AUTOSAR XML (schema 4-3-0)
package /ComponentTypes
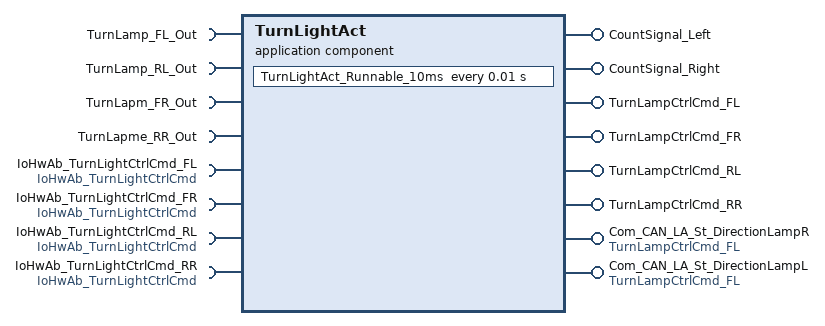
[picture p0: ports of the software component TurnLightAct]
  application sw component type TurnLightAct
    6 x provide port:
      CountSignal_Left: nonqueued-sender-com-spec{data-element=u8_Signal, init-value=0}, provided-interface=CountSignal_Left
      CountSignal_Right: nonqueued-sender-com-spec{data-element=u8_Signal, init-value=0}, provided-interface=CountSignal_Right
      TurnLampCtrlCmd_FL: nonqueued-sender-com-spec{data-element=u8_signal, init-value=0}, provided-interface=TurnLampCtrlCmd_FL
      TurnLampCtrlCmd_FR: nonqueued-sender-com-spec{data-element=u8_signa, init-value=0}, provided-interface=TurnLampCtrlCmd_FR
      TurnLampCtrlCmd_RL: nonqueued-sender-com-spec{data-element=u8_signal, init-value=0}, provided-interface=TurnLampCtrlCmd_RL
      TurnLampCtrlCmd_RR: nonqueued-sender-com-spec{data-element=u8_signal, init-value=0}, provided-interface=TurnLampCtrlCmd_RR
    4 x require port, all with nonqueued-receiver-com-spec{data-element=u8_Signal, init-value=0}:
      TurnLamp_FL_Out: required-interface=TurnLamp_FL_Out
      TurnLamp_RL_Out: required-interface=TurnLamp_RL_Out
      TurnLapm_FR_Out: required-interface=TurnLapm_FR_Out
      TurnLapme_RR_Out: required-interface=TurnLapme_RR_Out
    provide port Com_CAN_LA_St_DirectionLampR: nonqueued-sender-com-spec{data-element=u8_signal, init-value=0}, provided-interface=TurnLampCtrlCmd_FL
    provide port Com_CAN_LA_St_DirectionLampL: nonqueued-sender-com-spec{data-element=u8_signal, init-value=0}, provided-interface=TurnLampCtrlCmd_FL
    4 x require port, all with client-com-spec=Operation, required-interface=IoHwAb_TurnLightCtrlCmd:
      IoHwAb_TurnLightCtrlCmd_FL
      IoHwAb_TurnLightCtrlCmd_FR
      IoHwAb_TurnLightCtrlCmd_RL
      IoHwAb_TurnLightCtrlCmd_RR
    behavior TurnLightAct_InternalBehavior
      timing event TMT_Runnable_10ms: start-on-event=TurnLightAct_Runnable_10ms, period=0.01
      runnable TurnLightAct_Runnable_10ms: minimum-start-interval=0.01
        data-receive-point-by-arguments:
          4 x access:
            REC_TurnLamp_FL_Out_u8_Signal: accessed-variable=TurnLamp_FL_Out.u8_Signal
            REC_TurnLamp_RL_Out_u8_Signal: accessed-variable=TurnLamp_RL_Out.u8_Signal
            REC_TurnLapm_FR_Out_u8_Signal: accessed-variable=TurnLapm_FR_Out.u8_Signal
            REC_TurnLapme_RR_Out_u8_Signal: accessed-variable=TurnLapme_RR_Out.u8_Signal
        data-send-points:
          8 x access:
            SEND_CountSignal_Left_u8_Signal: accessed-variable=CountSignal_Left.u8_Signal
            SEND_CountSignal_Right_u8_Signal: accessed-variable=CountSignal_Right.u8_Signal
            SEND_TurnLampCtrlCmd_FL_u8_signal: accessed-variable=TurnLampCtrlCmd_FL.u8_signal
            SEND_TurnLampCtrlCmd_FR_u8_signa: accessed-variable=TurnLampCtrlCmd_FR.u8_signa
            SEND_TurnLampCtrlCmd_RL_u8_signal: accessed-variable=TurnLampCtrlCmd_RL.u8_signal
            SEND_TurnLampCtrlCmd_RR_u8_signal: accessed-variable=TurnLampCtrlCmd_RR.u8_signal
            SEND_Com_CAN_LA_St_DirectionLampL_u8_signal: accessed-variable=Com_CAN_LA_St_DirectionLampL.u8_signal
            SEND_Com_CAN_LA_St_DirectionLampR_u8_signal: accessed-variable=Com_CAN_LA_St_DirectionLampR.u8_signal
        4 x sync call:
          SC_IoHwAb_TurnLightCtrlCmd_FL_Operation: operation=IoHwAb_TurnLightCtrlCmd_FL.Operation
          SC_IoHwAb_TurnLightCtrlCmd_FR_Operation: operation=IoHwAb_TurnLightCtrlCmd_FR.Operation
          SC_IoHwAb_TurnLightCtrlCmd_RL_Operation: operation=IoHwAb_TurnLightCtrlCmd_RL.Operation
          SC_IoHwAb_TurnLightCtrlCmd_RR_Operation: operation=IoHwAb_TurnLightCtrlCmd_RR.Operation
  swc implementation TurnLightAct_Implementation: behavior=TurnLightAct_InternalBehavior
